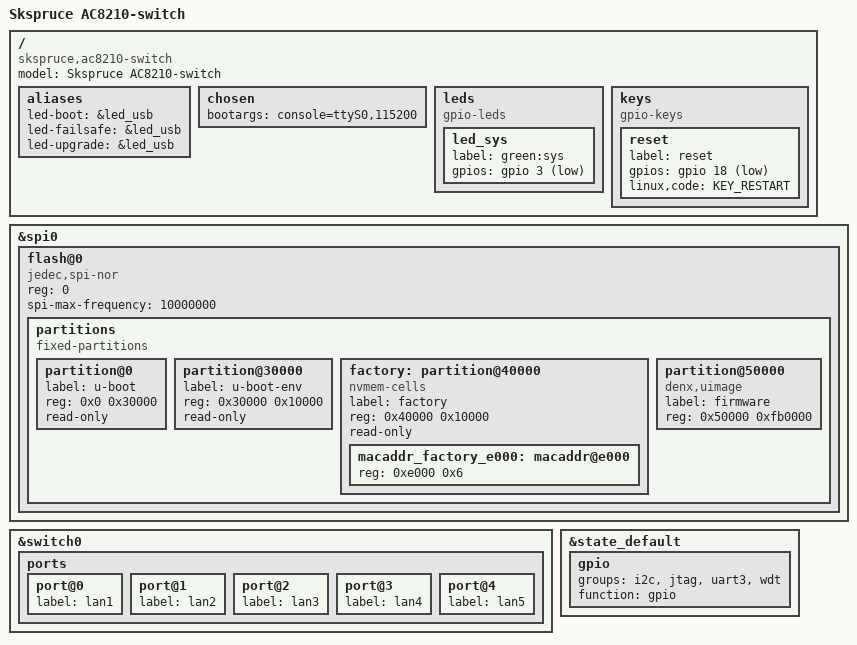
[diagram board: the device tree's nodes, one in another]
// SPDX-License-Identifier: GPL-2.0-or-later OR MIT

#include "mt7621.dtsi"

#include <dt-bindings/gpio/gpio.h>
#include <dt-bindings/input/input.h>

/ {
	compatible = "skspruce,ac8210-switch", "mediatek,mt7621-soc";
	model = "Skspruce AC8210-switch";

	aliases {
		led-boot = &led_usb;
		led-failsafe = &led_usb;
		led-upgrade = &led_usb;
	};

	chosen {
		bootargs = "console=ttyS0,115200";
	};
	
	leds {
		compatible = "gpio-leds";
				
		led_sys {
			label = "green:sys";
			gpios = <&gpio 3 GPIO_ACTIVE_LOW>;
		};
	};

	keys {
		compatible = "gpio-keys";

		reset {
			label = "reset";
			gpios = <&gpio 18 GPIO_ACTIVE_LOW>;
			linux,code = <KEY_RESTART>;
		};
	};
};

&spi0 {
	status = "okay";

	flash@0 {
		compatible = "jedec,spi-nor";
		reg = <0>;
		spi-max-frequency = <10000000>;

		partitions {
			compatible = "fixed-partitions";
			#address-cells = <1>;
			#size-cells = <1>;

			partition@0 {
				label = "u-boot";
				reg = <0x0 0x30000>;
				read-only;
			};

			partition@30000 {
				label = "u-boot-env";
				reg = <0x30000 0x10000>;
				read-only;
			};

			factory: partition@40000 {
				label = "factory";
				reg = <0x40000 0x10000>;
				read-only;
			};

			partition@50000 {
				compatible = "denx,uimage";
				label = "firmware";
				reg = <0x50000 0xfb0000>;
			};
		};
	};
};

&switch0 {
	ports {
		port@0 {
			status = "okay";
			label = "lan1";
		};

		port@1 {
			status = "okay";
			label = "lan2";
		};

		port@2 {
			status = "okay";
			label = "lan3";
		};

		port@3 {
			status = "okay";
			label = "lan4";
		};

		port@4 {
			status = "okay";
			label = "lan5";
		};
	};
};

&state_default {
	gpio {
		groups = "i2c", "jtag", "uart3", "wdt";
		function = "gpio";
	};
};

&factory {
	compatible = "nvmem-cells";
	#address-cells = <1>;
	#size-cells = <1>;

	macaddr_factory_e000: macaddr@e000 {
		reg = <0xe000 0x6>;
	};
};
